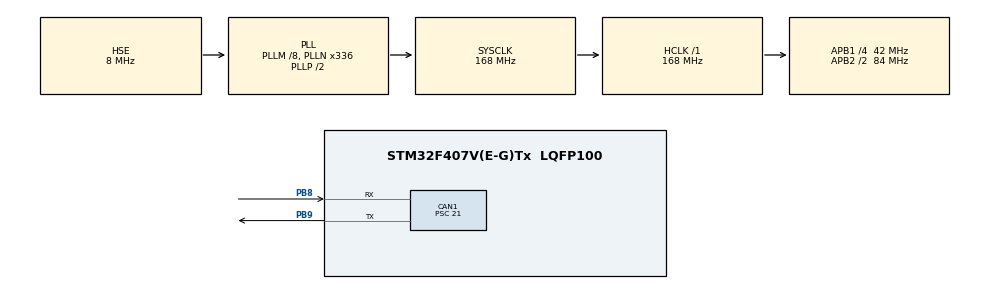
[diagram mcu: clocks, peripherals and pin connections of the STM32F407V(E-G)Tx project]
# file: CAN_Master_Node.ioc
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CAN1.BS1=CAN_BS1_13TQ
CAN1.BS2=CAN_BS2_2TQ
CAN1.CalculateTimeQuantum=500.0
CAN1.Mode=CAN_MODE_NORMAL
CAN1.NART=ENABLE
CAN1.Prescaler=21
Mcu.Family=STM32F4
Mcu.Name=STM32F407V(E-G)Tx
Mcu.Package=LQFP100
NVIC.CAN1_RX0_IRQn=true\:15\:0\:true\:false\:true\:true\:true
NVIC.CAN1_TX_IRQn=true\:15\:0\:true\:false\:true\:true\:true
NVIC.PriorityGroup=NVIC_PRIORITYGROUP_4
NVIC.TIM2_IRQn=true\:0\:0\:false\:false\:true\:true\:true
PA13.Mode=Serial_Wire
PA13.Signal=SYS_JTMS-SWDIO
PA14.Mode=Serial_Wire
PA14.Signal=SYS_JTCK-SWCLK
PB8.Mode=Master
PB8.Signal=CAN1_RX
PB9.Mode=Master
PB9.Signal=CAN1_TX
PH0-OSC_IN.Mode=HSE-External-Oscillator
PH0-OSC_IN.Signal=RCC_OSC_IN
PH1-OSC_OUT.Mode=HSE-External-Oscillator
PH1-OSC_OUT.Signal=RCC_OSC_OUT
ProjectManager.HeapSize=0x200
ProjectManager.StackSize=0x400
ProjectManager.TargetToolchain=SW4STM32
RCC.48MHZClocksFreq_Value=48000000
RCC.AHBFreq_Value=168000000
RCC.APB1CLKDivider=RCC_HCLK_DIV4
RCC.APB1Freq_Value=42000000
RCC.APB1TimFreq_Value=84000000
RCC.APB2CLKDivider=RCC_HCLK_DIV2
RCC.APB2Freq_Value=84000000
RCC.APB2TimFreq_Value=168000000
RCC.CortexFreq_Value=168000000
RCC.HCLKFreq_Value=168000000
RCC.HSE_VALUE=8000000
RCC.HSI_VALUE=16000000
RCC.LSE_VALUE=32768
RCC.PLLM=8
RCC.PLLN=336
RCC.PLLQ=7
RCC.PLLSourceVirtual=RCC_PLLSOURCE_HSE
RCC.SYSCLKFreq_VALUE=168000000
RCC.SYSCLKSource=RCC_SYSCLKSOURCE_PLLCLK
RCC.VCOOutputFreq_Value=336000000
TIM2.Period=1000
TIM2.Prescaler=42000
TIM2.TIM_MasterOutputTrigger=TIM_TRGO_UPDATE
VP_TIM2_VS_ClockSourceINT.Mode=Internal
board=STM32F407G-DISC1

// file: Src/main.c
/* USER CODE BEGIN Header */
/**
  ******************************************************************************
  * @file           : main.c
  * @brief          : Main program body
  ******************************************************************************
  * @attention
  *
  * <h2><center>&copy; Copyright (c) 2020 STMicroelectronics.
  * All rights reserved.</center></h2>
  *
  * This software component is licensed by ST under BSD 3-Clause license,
  * the "License"; You may not use this file except in compliance with the
  * License. You may obtain a copy of the License at:
  *                        opensource.org/licenses/BSD-3-Clause
  *
  ******************************************************************************
  */
/* USER CODE END Header */

#include "main.h"

/* USER CODE BEGIN Includes */
#include "string.h"
#include "stdio.h"
#include "math.h"
/* USER CODE END Includes */

/* USER CODE BEGIN PM */
#define CVAL 0.072f
/* USER CODE END PM */

CAN_HandleTypeDef hcan1;

TIM_HandleTypeDef htim2;

/* USER CODE BEGIN PV */

CAN_RxHeaderTypeDef RxHeader;
CAN_FilterTypeDef sFilterConfig;
CAN_TxHeaderTypeDef TxHeader;
uint32_t TxMailbox;
uint8_t adcArray[3];

float accel_min = 0, accel_max = 2.0, accel_t, accel_net;
float decel_min = 0, decel_max = 6.0, decel_t;
float current_speed = 0, current_speed_kmph;
float time1_t = 1;
uint8_t once=0;

uint8_t steer_angle1, steer_angle2, steer_thres = 35, temp=0;

/* USER CODE END PV */

void SystemClock_Config(void);
static void MX_GPIO_Init(void);
static void MX_CAN1_Init(void);
static void MX_TIM2_Init(void);

/* USER CODE BEGIN PFP */
//void CAN_Rx(void);
void CAN_Filer_Config(void);
void HAL_CAN_TxMailbox0CompleteCallback(CAN_HandleTypeDef *hcan);
void HAL_CAN_TxMailbox1CompleteCallback(CAN_HandleTypeDef *hcan);
void HAL_CAN_TxMailbox2CompleteCallback(CAN_HandleTypeDef *hcan);
void HAL_TIM_PeriodElapsedCallback(TIM_HandleTypeDef *htim);

float map(long x, long in_min, long in_max, float out_min, float out_max) {
  float temp = (float)( (x - in_min) * (out_max - out_min) / (in_max - in_min) + out_min);
	return (temp);
}

/* USER CODE END PFP */

int main(void)
{

  /* MCU Configuration--------------------------------------------------------*/

  /* Reset of all peripherals, Initializes the Flash interface and the Systick. */
  HAL_Init();

  /* Configure the system clock */
  SystemClock_Config();

  /* Initialize all configured peripherals */
  MX_GPIO_Init();
  MX_CAN1_Init();
  MX_TIM2_Init();

  /* USER CODE BEGIN 2 */
  CAN_Filer_Config();

  HAL_CAN_ActivateNotification(&hcan1, CAN_IT_TX_MAILBOX_EMPTY | CAN_IT_RX_FIFO0_MSG_PENDING );

  if( HAL_CAN_Start(&hcan1)!= HAL_OK)
  {
	  Error_Handler();
  }

  //HAL_TIM_Base_Start_IT(&htim2);

  /* USER CODE END 2 */

  /* Infinite loop */
  while (1)
  {

  }
}

void SystemClock_Config(void)
{
  RCC_OscInitTypeDef RCC_OscInitStruct = {0};
  RCC_ClkInitTypeDef RCC_ClkInitStruct = {0};

  /** Configure the main internal regulator output voltage
  */
  __HAL_RCC_PWR_CLK_ENABLE();
  __HAL_PWR_VOLTAGESCALING_CONFIG(PWR_REGULATOR_VOLTAGE_SCALE1);
  /** Initializes the CPU, AHB and APB busses clocks
  */
  RCC_OscInitStruct.OscillatorType = RCC_OSCILLATORTYPE_HSE;
  RCC_OscInitStruct.HSEState = RCC_HSE_ON;
  RCC_OscInitStruct.PLL.PLLState = RCC_PLL_ON;
  RCC_OscInitStruct.PLL.PLLSource = RCC_PLLSOURCE_HSE;
  RCC_OscInitStruct.PLL.PLLM = 8;
  RCC_OscInitStruct.PLL.PLLN = 336;
  RCC_OscInitStruct.PLL.PLLP = RCC_PLLP_DIV2;
  RCC_OscInitStruct.PLL.PLLQ = 7;
  if (HAL_RCC_OscConfig(&RCC_OscInitStruct) != HAL_OK)
  {
    Error_Handler();
  }
  /** Initializes the CPU, AHB and APB busses clocks
  */
  RCC_ClkInitStruct.ClockType = RCC_CLOCKTYPE_HCLK|RCC_CLOCKTYPE_SYSCLK
                              |RCC_CLOCKTYPE_PCLK1|RCC_CLOCKTYPE_PCLK2;
  RCC_ClkInitStruct.SYSCLKSource = RCC_SYSCLKSOURCE_PLLCLK;
  RCC_ClkInitStruct.AHBCLKDivider = RCC_SYSCLK_DIV1;
  RCC_ClkInitStruct.APB1CLKDivider = RCC_HCLK_DIV4;
  RCC_ClkInitStruct.APB2CLKDivider = RCC_HCLK_DIV2;

  if (HAL_RCC_ClockConfig(&RCC_ClkInitStruct, FLASH_LATENCY_5) != HAL_OK)
  {
    Error_Handler();
  }
}

static void MX_CAN1_Init(void)
{

  hcan1.Instance = CAN1;
  hcan1.Init.Prescaler = 21;
  hcan1.Init.Mode = CAN_MODE_NORMAL;
  hcan1.Init.SyncJumpWidth = CAN_SJW_1TQ;
  hcan1.Init.TimeSeg1 = CAN_BS1_13TQ;
  hcan1.Init.TimeSeg2 = CAN_BS2_2TQ;
  hcan1.Init.TimeTriggeredMode = DISABLE;
  hcan1.Init.AutoBusOff = DISABLE;
  hcan1.Init.AutoWakeUp = DISABLE;
  hcan1.Init.AutoRetransmission = ENABLE;
  hcan1.Init.ReceiveFifoLocked = DISABLE;
  hcan1.Init.TransmitFifoPriority = DISABLE;
  if (HAL_CAN_Init(&hcan1) != HAL_OK)
  {
    Error_Handler();
  }

}

static void MX_TIM2_Init(void)
{

  TIM_ClockConfigTypeDef sClockSourceConfig = {0};
  TIM_MasterConfigTypeDef sMasterConfig = {0};

  htim2.Instance = TIM2;
  htim2.Init.Prescaler = 42000;
  htim2.Init.CounterMode = TIM_COUNTERMODE_UP;
  htim2.Init.Period = 1000;
  htim2.Init.ClockDivision = TIM_CLOCKDIVISION_DIV1;
  htim2.Init.AutoReloadPreload = TIM_AUTORELOAD_PRELOAD_DISABLE;
  if (HAL_TIM_Base_Init(&htim2) != HAL_OK)
  {
    Error_Handler();
  }
  sClockSourceConfig.ClockSource = TIM_CLOCKSOURCE_INTERNAL;
  if (HAL_TIM_ConfigClockSource(&htim2, &sClockSourceConfig) != HAL_OK)
  {
    Error_Handler();
  }
  sMasterConfig.MasterOutputTrigger = TIM_TRGO_UPDATE;
  sMasterConfig.MasterSlaveMode = TIM_MASTERSLAVEMODE_DISABLE;
  if (HAL_TIMEx_MasterConfigSynchronization(&htim2, &sMasterConfig) != HAL_OK)
  {
    Error_Handler();
  }

}

static void MX_GPIO_Init(void)
{

  /* GPIO Ports Clock Enable */
  __HAL_RCC_GPIOH_CLK_ENABLE();
  __HAL_RCC_GPIOA_CLK_ENABLE();
  __HAL_RCC_GPIOB_CLK_ENABLE();

}

/* USER CODE BEGIN 4 */

void CAN_Filer_Config(void)
{
	sFilterConfig.FilterActivation = ENABLE;
	sFilterConfig.FilterBank = 0;
	sFilterConfig.FilterFIFOAssignment = CAN_RX_FIFO0;
	sFilterConfig.FilterIdHigh = 0x0000;
	sFilterConfig.FilterIdLow = 0x0000;
	sFilterConfig.FilterMaskIdHigh = 0x000;
	sFilterConfig.FilterMaskIdLow = 0x0000;
	sFilterConfig.FilterMode = CAN_FILTERMODE_IDMASK;
	sFilterConfig.FilterScale = CAN_FILTERSCALE_32BIT;

	if(HAL_CAN_ConfigFilter(&hcan1, &sFilterConfig)!= HAL_OK)
	{
		Error_Handler();
	}

}

//void CAN_Rx(void)
//{
//	while(! HAL_CAN_GetRxFifoFillLevel(&hcan1, CAN_RX_FIFO0));
//
//	if(HAL_CAN_GetRxMessage(&hcan1, CAN_RX_FIFO0,&RxHeader, rcv_array) != HAL_OK)
//	{
//		Error_Handler();
//	}
//
//	sprintf(msg, "Message Received : %s\r\n", rcv_array);
//	HAL_UART_Transmit(&huart4, (uint8_t*)msg, strlen(msg), HAL_MAX_DELAY);
//}

void HAL_CAN_TxMailbox0CompleteCallback(CAN_HandleTypeDef *hcan)
{

//	sprintf(msg, "Message Transmitted M0\r\n");
//
//	HAL_UART_Transmit(&huart4, (uint8_t*)msg, strlen(msg), HAL_MAX_DELAY);

}

void HAL_CAN_TxMailbox1CompleteCallback(CAN_HandleTypeDef *hcan)
{

//	sprintf(msg, "Message Transmitted M1\r\n");
//
//	HAL_UART_Transmit(&huart4, (uint8_t*)msg, strlen(msg), HAL_MAX_DELAY);

}

void HAL_CAN_TxMailbox2CompleteCallback(CAN_HandleTypeDef *hcan)
{

//	sprintf(msg, "Message Transmitted M2\r\n");
//
//	HAL_UART_Transmit(&huart4, (uint8_t*)msg, strlen(msg), HAL_MAX_DELAY);

}

void HAL_CAN_RxFifo0MsgPendingCallback(CAN_HandleTypeDef *hcan)
{

	if(HAL_CAN_GetRxMessage(&hcan1, CAN_RX_FIFO0,&RxHeader, adcArray) != HAL_OK)
		{
			Error_Handler();
		}

	if(!once)
	{
		HAL_TIM_Base_Start_IT(&htim2);
		steer_angle1 = adcArray[2];
		steer_angle2 = steer_angle1;
		once++;
	}

//	sprintf(msg, "Message Received : %s\r\n", rcv_array);
//	HAL_UART_Transmit(&huart4, (uint8_t*)msg, strlen(msg), HAL_MAX_DELAY);

}

void HAL_TIM_PeriodElapsedCallback(TIM_HandleTypeDef *htim)
{

	// tim_count++;
	/**************Accelerator and Brake**************/
		accel_t = map(adcArray[0], 0, 255, accel_min, accel_max);
		decel_t = map(adcArray[1], 0, 255, decel_min, decel_max);

		accel_net = accel_t - (CVAL*current_speed) - decel_t;

		if(current_speed<=0 && adcArray[1]>2) {
				current_speed = 0;
		}
		else {
			current_speed = current_speed + ((accel_net * time1_t)/2);
		}
//		accel_net = accel_t - (CVAL*current_speed) - decel_t;

		/*********** Steering Logic ***********/
		if(current_speed>8.33){
			if((steer_angle2-steer_angle1)>steer_thres || (steer_angle1-steer_angle2)>steer_thres )
			{
				//temp = 1;
				temp++;
			}
			else{
				//temp = 0;
			}
		}
		steer_angle1 = steer_angle2;
		steer_angle2 = adcArray[2];

}

/* USER CODE END 4 */

void Error_Handler(void)
{
}

/************************ (C) COPYRIGHT STMicroelectronics *****END OF FILE****/
